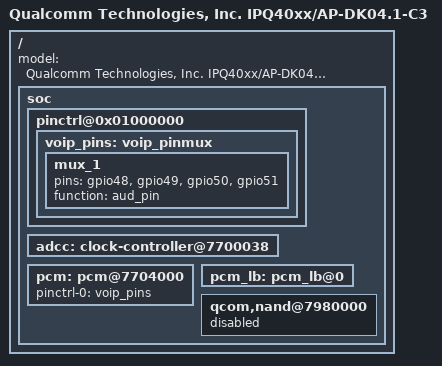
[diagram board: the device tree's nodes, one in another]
/* Copyright (c) 2015, The Linux Foundation. All rights reserved.
 *
 * Permission to use, copy, modify, and/or distribute this software for any
 * purpose with or without fee is hereby granted, provided that the above
 * copyright notice and this permission notice appear in all copies.
 *
 * THE SOFTWARE IS PROVIDED "AS IS" AND THE AUTHOR DISCLAIMS ALL WARRANTIES
 * WITH REGARD TO THIS SOFTWARE INCLUDING ALL IMPLIED WARRANTIES OF
 * MERCHANTABILITY AND FITNESS. IN NO EVENT SHALL THE AUTHOR BE LIABLE FOR
 * ANY SPECIAL, DIRECT, INDIRECT, OR CONSEQUENTIAL DAMAGES OR ANY DAMAGES
 * WHATSOEVER RESULTING FROM LOSS OF USE, DATA OR PROFITS, WHETHER IN AN
 * ACTION OF CONTRACT, NEGLIGENCE OR OTHER TORTIOUS ACTION, ARISING OUT OF
 * OR IN CONNECTION WITH THE USE OR PERFORMANCE OF THIS SOFTWARE.
 *
 */

#include "qcom-ipq40xx-ap.dk04.1.dtsi"
#include "qcom-ipq40xx-lcdc.dtsi"
#include "qcom-ipq40xx-lcdpanel.dtsi"
#include "qcom-ipq40xx-audio.dtsi"

/ {
	model = "Qualcomm Technologies, Inc. IPQ40xx/AP-DK04.1-C3";

	soc {
		pinctrl@0x01000000 {
			voip_pins: voip_pinmux {
				mux_1 {
					pins = "gpio48", "gpio49", "gpio50", "gpio51";
					function = "aud_pin";
				};
			};
		};

		adcc: clock-controller@7700038 {
			status = "ok";
		};

		/* Enable VOIP Interfaces */
		pcm: pcm@7704000 {
			status = "ok";
			pinctrl-0 = <&voip_pins>;
			pinctrl-names = "default";
		};

		pcm_lb: pcm_lb@0 {
			status = "ok";
		};

		qcom,nand@7980000 {
			status = "disabled";
		};

	};
};
